# ADuCM302x register map
Vendor: Analog Devices; Series: ADuCM302x; File version: 1p0
CPU: CM3 r0p1, little endian, no MPU, no FPU, 3 interrupt priority bits
Registers are 32-bit, read-write, reset 0x0 unless marked. A register's access mark holds for its fields unless they carry their own. Offsets are from the block's base; [hi:lo] are bit positions.

## I2C0 — I2C Master/Slave
Base 0x40003000
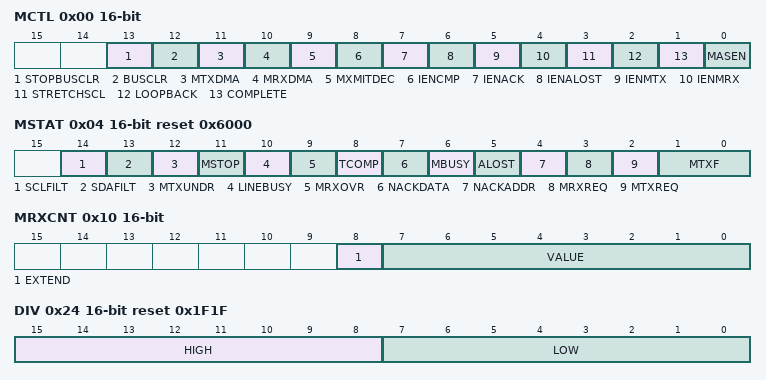
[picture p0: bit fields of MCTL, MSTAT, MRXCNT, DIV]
0x00 MCTL 16-bit — Master Control
  [13] STOPBUSCLR range 0x00000000..0x00000001 — Prestop Bus-Clear
  [12] BUSCLR range 0x00000000..0x00000001 — Bus-Clear Enable
  [11] MTXDMA wo range 0x00000000..0x00000001 — Enable master Tx DMA request
  [10] MRXDMA wo range 0x00000000..0x00000001 — Enable master Rx DMA request
  [9] MXMITDEC range 0x00000000..0x00000001 — Decrement master TX FIFO status when a byte has been transmitted
  [8] IENCMP range 0x00000000..0x00000001 — Transaction completed (or stop detected) interrupt enable
  [7] IENACK range 0x00000000..0x00000001 — ACK not received interrupt enable
  [6] IENALOST range 0x00000000..0x00000001 — Arbitration lost interrupt enable
  [5] IENMTX range 0x00000000..0x00000001 — Transmit request interrupt enable
  [4] IENMRX range 0x00000000..0x00000001 — Receive request interrupt enable
  [3] STRETCHSCL range 0x00000000..0x00000001 — Stretch SCL enable
  [2] LOOPBACK range 0x00000000..0x00000001 — Internal loopback enable
  [1] COMPLETE range 0x00000000..0x00000001 — Start back-off disable
  [0] MASEN range 0x00000000..0x00000001 — Master enable
0x04 MSTAT 16-bit reset 0x6000 — Master Status
  [14] SCLFILT ro — State of SCL Line
  [13] SDAFILT ro — State of SDA Line
  [12] MTXUNDR ro — Master Transmit Underflow
  [11] MSTOP ro — STOP driven by this I2C Master
  [10] LINEBUSY ro — Line is busy
  [9] MRXOVR ro — Master Receive FIFO overflow
  [8] TCOMP ro — Transaction complete or stop detected
  [7] NACKDATA ro — ACK not received in response to data write
  [6] MBUSY ro — Master busy
  [5] ALOST ro — Arbitration lost
  [4] NACKADDR ro — ACK not received in response to an address
  [3] MRXREQ ro — Master Receive request
  [2] MTXREQ range 0x00000000..0x00000001 — This bit will assert when the direction bit is 0 and transmit FIFO is not full
  [1:0] MTXF ro — Master Transmit FIFO status
0x08 MRX 16-bit — Master Receive Data
  [7:0] VALUE ro — Master receive register
0x0C MTX 16-bit — Master Transmit Data
  [7:0] VALUE range 0x00000000..0x000000FF — Master transmit register
0x10 MRXCNT 16-bit — Master Receive Data Count
  [8] EXTEND range 0x00000000..0x00000001 — Extended read
  [7:0] VALUE range 0x00000000..0x000000FF — Receive count
0x14 MCRXCNT 16-bit — Master Current Receive Data Count
  [7:0] VALUE ro — Current receive count
0x18 ADDR1 16-bit — Master Address Byte 1
  [7:0] VALUE range 0x00000000..0x000000FF — Address byte 1
0x1C ADDR2 16-bit — Master Address Byte 2
  [7:0] VALUE range 0x00000000..0x000000FF — Address byte 2
0x20 BYT 16-bit — Start Byte
  [7:0] SBYTE range 0x00000000..0x000000FF — Start byte
0x24 DIV 16-bit reset 0x1F1F — Serial Clock Period Divisor
  [15:8] HIGH range 0x00000000..0x000000FF — Serial clock high time
  [7:0] LOW range 0x00000000..0x000000FF — Serial clock low time
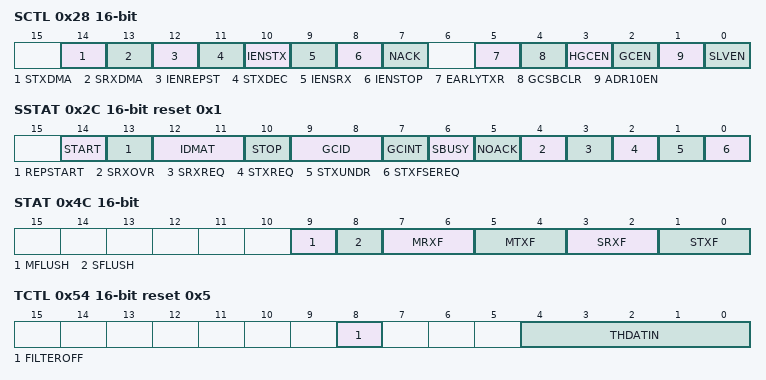
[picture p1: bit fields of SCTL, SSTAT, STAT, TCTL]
0x28 SCTL 16-bit — Slave Control
  [14] STXDMA range 0x00000000..0x00000001 — Enable slave Tx DMA request
  [13] SRXDMA range 0x00000000..0x00000001 — Enable slave Rx DMA request
  [12] IENREPST range 0x00000000..0x00000001 — Repeated start interrupt enable
  [11] STXDEC range 0x00000000..0x00000001 — Decrement Slave Tx FIFO status when a byte has been transmitted
  [10] IENSTX range 0x00000000..0x00000001 — Slave Transmit request interrupt enable
  [9] IENSRX range 0x00000000..0x00000001 — Slave Receive request interrupt enable
  [8] IENSTOP range 0x00000000..0x00000001 — Stop condition detected interrupt enable
  [7] NACK range 0x00000000..0x00000001 — NACK next communication
  [5] EARLYTXR range 0x00000000..0x00000001 — Early transmit request mode
  [4] GCSBCLR wo range 0x00000000..0x00000001 — General call status bit clear
  [3] HGCEN range 0x00000000..0x00000001 — Hardware general call enable
  [2] GCEN range 0x00000000..0x00000001 — General call enable
  [1] ADR10EN range 0x00000000..0x00000001 — Enabled 10-bit addressing
  [0] SLVEN range 0x00000000..0x00000001 — Slave enable
0x2C SSTAT 16-bit reset 0x1 — Slave I2C Status/Error/IRQ
  [14] START ro — Start and matching address
  [13] REPSTART ro — Repeated start and matching address
  [12:11] IDMAT ro — Device ID matched
  [10] STOP ro — Stop after start and matching address
  [9:8] GCID ro — General ID
  [7] GCINT ro — General call interrupt
  [6] SBUSY ro — Slave busy
  [5] NOACK ro — Ack not generated by the slave
  [4] SRXOVR ro — Slave Receive FIFO overflow
  [3] SRXREQ ro — Slave Receive request
  [2] STXREQ ro — When read is slave transmit request; when write is clear slave transmit interrupt bit
  [1] STXUNDR ro — Slave Transmit FIFO underflow
  [0] STXFSEREQ range 0x00000000..0x00000001 — Slave Tx FIFO Status or early request
0x30 SRX 16-bit — Slave Receive
  [7:0] VALUE ro — Slave receive register
0x34 STX 16-bit — Slave Transmit
  [7:0] VALUE range 0x00000000..0x000000FF — Slave transmit register
0x38 ALT 16-bit — Hardware General Call ID
  [7:0] ID range 0x00000000..0x000000FF — Slave Alt
0x3C ID0 16-bit — First Slave Address Device ID
  [7:0] VALUE range 0x00000000..0x000000FF — Slave device ID 0
0x40 ID1 16-bit — Second Slave Address Device ID
  [7:0] VALUE range 0x00000000..0x000000FF — Slave device ID 1
0x44 ID2 16-bit — Third Slave Address Device ID
  [7:0] VALUE range 0x00000000..0x000000FF — Slave device ID 2
0x48 ID3 16-bit — Fourth Slave Address Device ID
  [7:0] VALUE range 0x00000000..0x000000FF — Slave device ID 3
0x4C STAT 16-bit — Master and Slave FIFO Status
  [9] MFLUSH wo range 0x00000000..0x00000001 — Flush the master transmit FIFO
  [8] SFLUSH wo range 0x00000000..0x00000001 — Flush the slave transmit FIFO
  [7:6] MRXF ro — Master receive FIFO status
  [5:4] MTXF ro — Master transmit FIFO status
  [3:2] SRXF ro — Slave receive FIFO status
  [1:0] STXF ro — Slave transmit FIFO status
0x50 SHCTL 16-bit — Shared Control
  [0] RST wo range 0x00000000..0x00000001 — Reset START STOP detect circuit
0x54 TCTL 16-bit reset 0x5 — Timing Control Register
  [8] FILTEROFF — Input Filter Control
  [4:0] THDATIN range 0x00000000..0x0000001F — Data In Hold Start
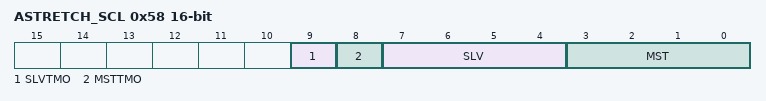
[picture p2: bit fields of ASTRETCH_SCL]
0x58 ASTRETCH_SCL 16-bit — Automatic Stretch SCL
  [9] SLVTMO ro — Slave automatic stretch timeout
  [8] MSTTMO ro — Master automatic stretch timeout
  [7:4] SLV range 0x00000000..0x0000000F — Slave automatic stretch mode
  [3:0] MST range 0x00000000..0x0000000F — Master automatic stretch mode

## Notices in the file
Copyright (c) 2014-2016 Analog Devices, Inc.  All Rights Reserved.
This software is proprietary and confidential to Analog Devices, Inc.
and its licensors.
